# STM32F30xxx register map
File version: 1.0
Registers are 32-bit, read-write, reset 0x0 unless marked. A register's access mark holds for its fields unless they carry their own. Offsets are from the block's base; [hi:lo] are bit positions; {n}, {i} and the like mark numbered series.

## SPI1 — Serial peripheral interface/Inter-IC sound
Base 0x40013000
Same registers: I2S2ext 0x40003400, SPI2 0x40003800, SPI3 0x40003C00, I2S3ext 0x40004000
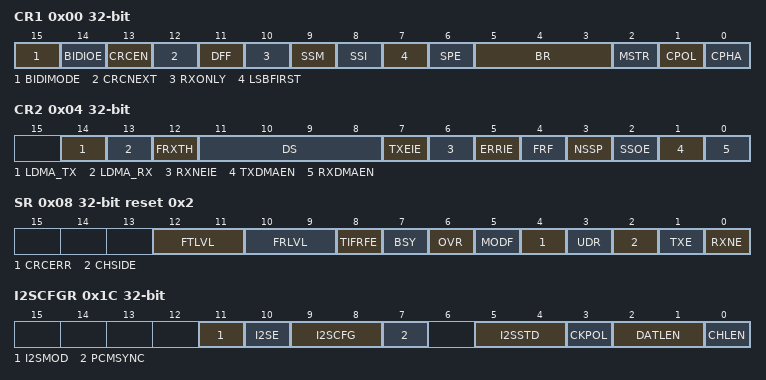
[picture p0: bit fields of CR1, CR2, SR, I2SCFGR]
0x00 CR1 — control register 1
  [15] BIDIMODE — Bidirectional data mode enable
  [14] BIDIOE — Output enable in bidirectional mode
  [13] CRCEN — Hardware CRC calculation enable
  [12] CRCNEXT — CRC transfer next
  [11] DFF — Data frame format
  [10] RXONLY — Receive only
  [9] SSM — Software slave management
  [8] SSI — Internal slave select
  [7] LSBFIRST — Frame format
  [6] SPE — SPI enable
  [5:3] BR — Baud rate control
  [2] MSTR — Master selection
  [1] CPOL — Clock polarity
  [0] CPHA — Clock phase
0x04 CR2 — control register 2
  [14] LDMA_TX — Last DMA transfer for transmission
  [13] LDMA_RX — Last DMA transfer for reception
  [12] FRXTH — FIFO reception threshold
  [11:8] DS — Data size
  [7] TXEIE — Tx buffer empty interrupt enable
  [6] RXNEIE — RX buffer not empty interrupt enable
  [5] ERRIE — Error interrupt enable
  [4] FRF — Frame format
  [3] NSSP — NSS pulse management
  [2] SSOE — SS output enable
  [1] TXDMAEN — Tx buffer DMA enable
  [0] RXDMAEN — Rx buffer DMA enable
0x08 SR access per field reset 0x2 — status register
  [12:11] FTLVL ro — FIFO transmission level
  [10:9] FRLVL ro — FIFO reception level
  [8] TIFRFE ro — TI frame format error
  [7] BSY ro — Busy flag
  [6] OVR ro — Overrun flag
  [5] MODF ro — Mode fault
  [4] CRCERR rw — CRC error flag
  [3] UDR ro — Underrun flag
  [2] CHSIDE ro — Channel side
  [1] TXE ro — Transmit buffer empty
  [0] RXNE ro — Receive buffer not empty
0x0C DR — data register
  [15:0] DR — Data register
0x10 CRCPR reset 0x7 — CRC polynomial register
  [15:0] CRCPOLY
0x14 RXCRCR ro — RX CRC register
  [15:0] RxCRC
0x18 TXCRCR ro — TX CRC register
  [15:0] TxCRC
0x1C I2SCFGR — I2S configuration register
  [11] I2SMOD — I2S mode selection
  [10] I2SE — I2S Enable
  [9:8] I2SCFG — I2S configuration mode
  [7] PCMSYNC — PCM frame synchronization
  [5:4] I2SSTD — I2S standard selection
  [3] CKPOL — Steady state clock polarity
  [2:1] DATLEN — Data length to be transferred
  [0] CHLEN — Channel length (number of bits per audio channel)
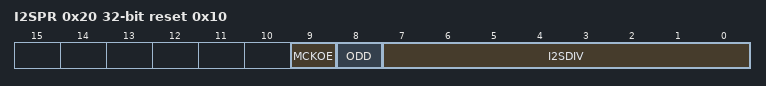
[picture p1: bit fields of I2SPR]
0x20 I2SPR reset 0x10 — I2S prescaler register
  [9] MCKOE — Master clock output enable
  [8] ODD — Odd factor for the prescaler
  [7:0] I2SDIV — I2S Linear prescaler

## EXTI — External interrupt/event controller
Base 0x40010400
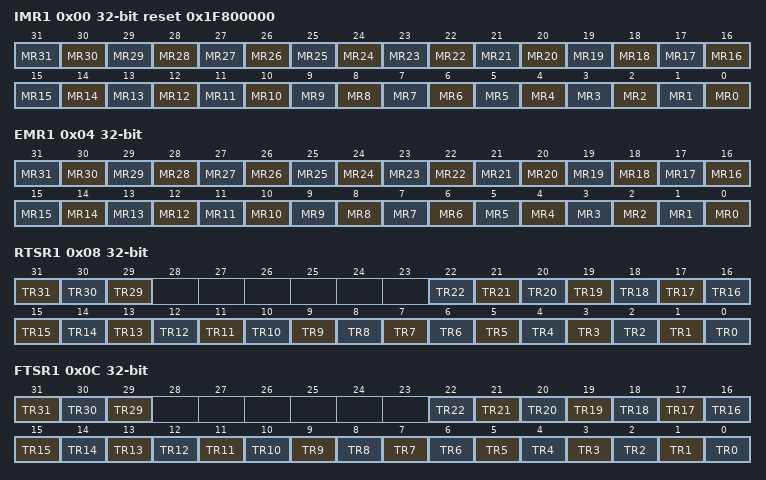
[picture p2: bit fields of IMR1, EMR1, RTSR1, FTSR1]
0x00 IMR1 reset 0x1F800000 — Interrupt mask register
  [n] MR{n} (n=0..31) — Interrupt Mask on line {n}
0x04 EMR1 — Event mask register
  [n] MR{n} (n=0..31) — Event Mask on line {n}
0x08 RTSR1 — Rising Trigger selection register
  [31] TR31 — Rising trigger event configuration of line 31
  [30] TR30 — Rising trigger event configuration of line 30
  [29] TR29 — Rising trigger event configuration of line 29
  [n] TR{n} (n=0..22) — Rising trigger event configuration of line {n}
0x0C FTSR1 — Falling Trigger selection register
  [31] TR31 — Falling trigger event configuration of line 31
  [30] TR30 — Falling trigger event configuration of line 30.
  [29] TR29 — Falling trigger event configuration of line 29
  [n] TR{n} (n=0..22) — Falling trigger event configuration of line {n}
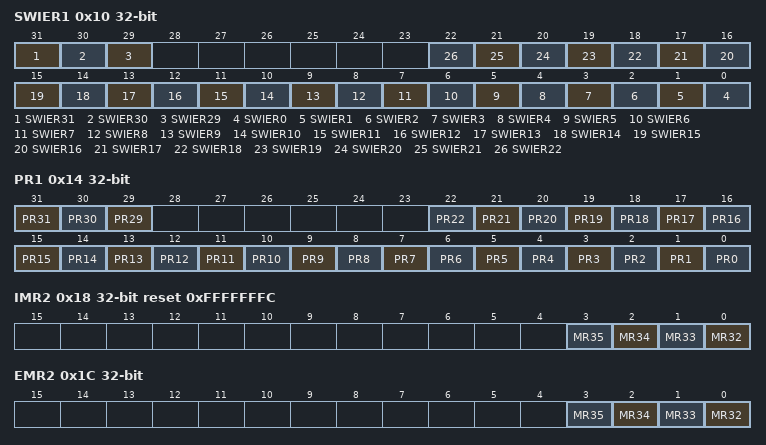
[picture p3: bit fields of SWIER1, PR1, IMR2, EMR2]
0x10 SWIER1 — Software interrupt event register
  [31] SWIER31 — Software Interrupt on line 319
  [30] SWIER30 — Software Interrupt on line 309
  [29] SWIER29 — Software Interrupt on line 29
  [n] SWIER{n} (n=0..22) — Software Interrupt on line {n}
0x14 PR1 — Pending register
  [31] PR31 — Pending bit 31
  [30] PR30 — Pending bit 30
  [29] PR29 — Pending bit 29
  [n] PR{n} (n=0..22) — Pending bit {n}
0x18 IMR2 reset 0xFFFFFFFC — Interrupt mask register
  [n-32] MR{n} (n=32..35) — Interrupt Mask on external/internal line {n}
0x1C EMR2 — Event mask register
  [n-32] MR{n} (n=32..35) — Event mask on external/internal line {n}
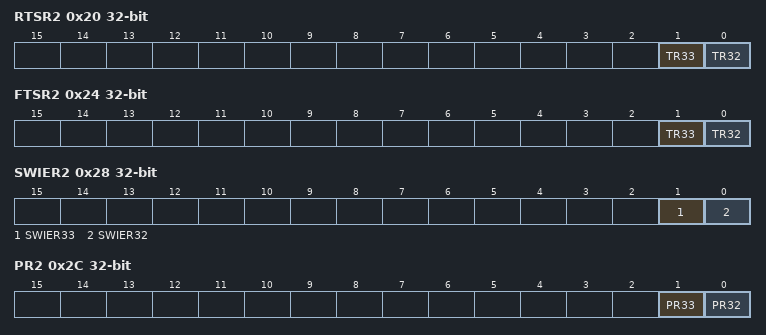
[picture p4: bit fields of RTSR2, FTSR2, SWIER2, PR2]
0x20 RTSR2 — Rising Trigger selection register
  [1] TR33 — Rising trigger event configuration bit of line 33
  [0] TR32 — Rising trigger event configuration bit of line 32
0x24 FTSR2 — Falling Trigger selection register
  [1] TR33 — Falling trigger event configuration bit of line 33
  [0] TR32 — Falling trigger event configuration bit of line 32
0x28 SWIER2 — Software interrupt event register
  [1] SWIER33 — Software interrupt on line 33
  [0] SWIER32 — Software interrupt on line 32
0x2C PR2 — Pending register
  [1] PR33 — Pending bit on line 33
  [0] PR32 — Pending bit on line 32
